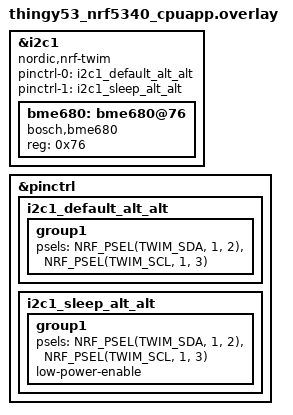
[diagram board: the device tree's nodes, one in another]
/*
 * Copyright (c) 2021-2022 Nordic Semiconductor ASA
 *
 * SPDX-License-Identifier: LicenseRef-Nordic-5-Clause
 */

i2c1: &i2c1 {
	compatible = "nordic,nrf-twim";
	status = "okay";

	pinctrl-0 = <&i2c1_default_alt_alt>;
	pinctrl-1 = <&i2c1_sleep_alt_alt>;
	pinctrl-names = "default", "sleep";
	bme680: bme680@76 {
		compatible = "bosch,bme680";
		reg = <0x76>;
	};
};

&pinctrl {
	i2c1_default_alt_alt: i2c1_default_alt_alt {
		group1 {
			psels = <NRF_PSEL(TWIM_SDA, 1, 2)>,
				<NRF_PSEL(TWIM_SCL, 1, 3)>;
		};
	};

	i2c1_sleep_alt_alt: i2c1_sleep_alt_alt {
		group1 {
			psels = <NRF_PSEL(TWIM_SDA, 1, 2)>,
				<NRF_PSEL(TWIM_SCL, 1, 3)>;
			low-power-enable;
		};
	};

};
